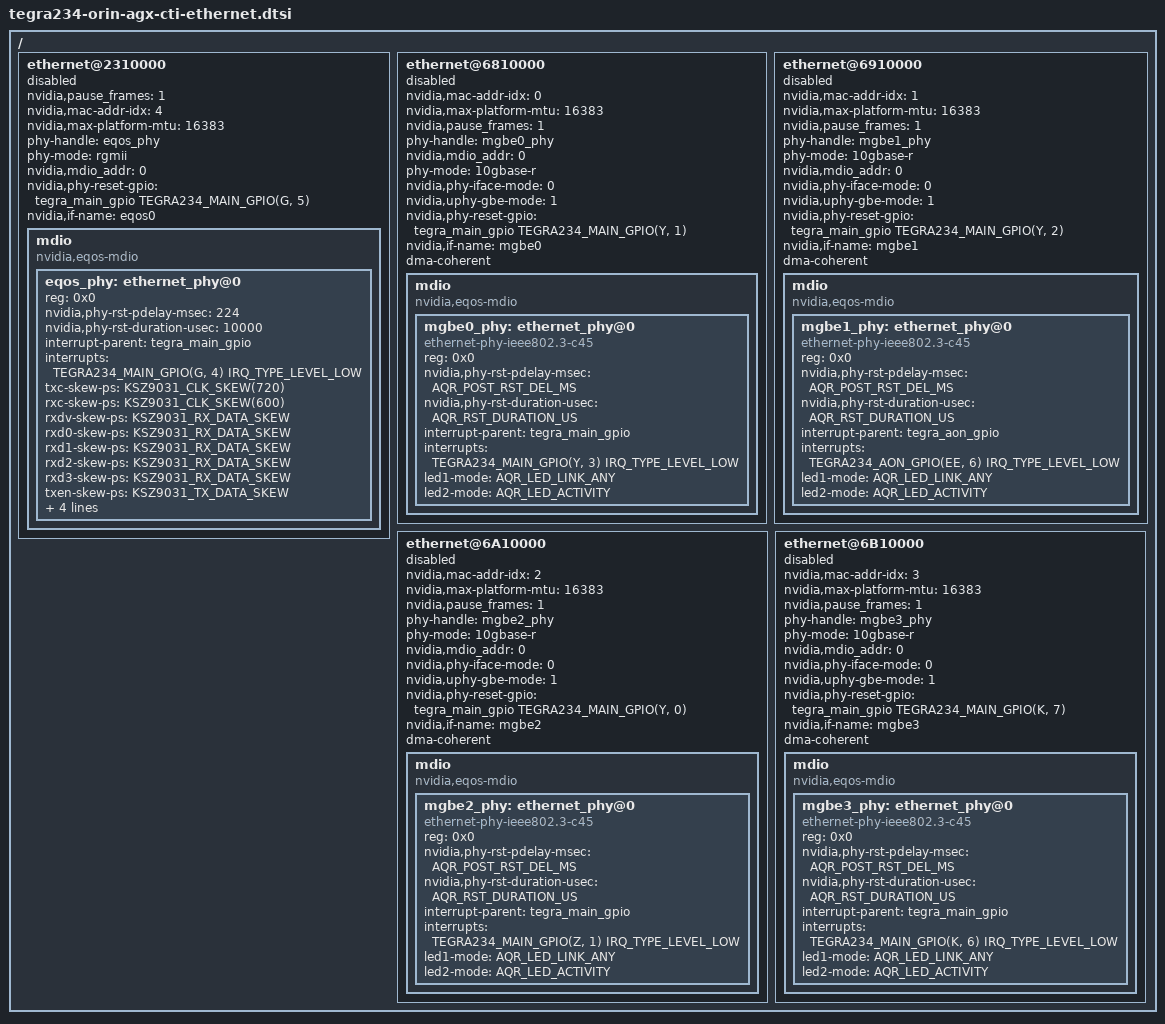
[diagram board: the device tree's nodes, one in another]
/*
 * Copyright (c) 2023, Connect Tech Inc.  All rights reserved.
 *
 * This program is free software; you can redistribute it and/or modify it
 * under the terms and conditions of the GNU General Public License,
 * version 2, as published by the Free Software Foundation.
 *
 * This program is distributed in the hope it will be useful, but WITHOUT
 * ANY WARRANTY; without even the implied warranty of MERCHANTABILITY or
 * FITNESS FOR A PARTICULAR PURPOSE.  See the GNU General Public License for
 * more details.
 *
 * You should have received a copy of the GNU General Public License
 * along with this program.  If not, see <http://www.gnu.org/licenses/>.
 */

#include <dt-bindings/gpio/tegra234-gpio.h>

//AQR113 LED Modes
#define AQR_LED_OFF         0x0000
#define AQR_LED_ACTIVITY    0x000F
#define AQR_LED_CONNECTING  0x0010
#define AQR_LED_LINK_100    0x0020
#define AQR_LED_LINK_1000   0x0040
#define AQR_LED_LINK_10000  0x0080
#define AQR_LED_LINK_10     0x2000
#define AQR_LED_LINK_2500   0x4000
#define AQR_LED_LINK_5000   0x8000
#define AQR_LED_LINK_ANY    0xE0E0

//Reset assert duration in microseconds
#define AQR_RST_DURATION_US 150000  //AQR113 min 100ms, using 150ms 

//Time to wait after reset in milliseconds
#define AQR_POST_RST_DEL_MS 1000     //Not specified in AQR113 DS, 1s is needed for FW to load

/*
 * Calculate the Device Tree Value for a Clk Skew Property
 * DT value of "900" is 0ps delay. Min is -900ps, max is +960ps 
 */
#define KSZ9031_CLK_SKEW(skew_ps) (900 + skew_ps)

/*
 * Calculate the Device Tree Value for a Data Skew Property
 * DT value of "420" is 0ps delay. Min is -400ps, max is +480ps 
 */
#define KSZ9031_DATA_SKEW(skew_ps) (420 + skew_ps)

#define KSZ9031_RX_DATA_SKEW KSZ9031_DATA_SKEW(0)   //0ns
#define KSZ9031_TX_DATA_SKEW KSZ9031_DATA_SKEW(0)   //0ns

/ {
    //EQOS 1GbE
    ethernet@2310000 {
		status = "disabled";
        nvidia,pause_frames = <1>;  //1=disabled
        nvidia,mac-addr-idx = <4>;
        nvidia,max-platform-mtu = <16383>;
		phy-handle = <&eqos_phy>;
        //Use RGMII not RGMII-ID (Internal Delay) to set custom skew values
        phy-mode = "rgmii";
        nvidia,mdio_addr = <0>;

        nvidia,phy-reset-gpio = <&tegra_main_gpio TEGRA234_MAIN_GPIO(G, 5) 0>;

        nvidia,if-name = "eqos0";

		mdio {
			compatible = "nvidia,eqos-mdio";
			#address-cells = <1>;
            #size-cells = <0>;
            eqos_phy: ethernet_phy@0 {
                reg = <0x0>;
                nvidia,phy-rst-pdelay-msec = <224>;
                nvidia,phy-rst-duration-usec = <10000>;
                interrupt-parent = <&tegra_main_gpio>;
                interrupts = <TEGRA234_MAIN_GPIO(G, 4) IRQ_TYPE_LEVEL_LOW>;

                //Clk to Data skew must be 1.5ns-2.0ns
                txc-skew-ps  = <KSZ9031_CLK_SKEW(720)>; //+0.72ns + +1.1ns (on-board) = +1.82ns 
                rxc-skew-ps  = <KSZ9031_CLK_SKEW(600)>; //+0.60ns + +1.2ns (built-in) = +1.80ns

                rxdv-skew-ps = <KSZ9031_RX_DATA_SKEW>; 
                rxd0-skew-ps = <KSZ9031_RX_DATA_SKEW>;
                rxd1-skew-ps = <KSZ9031_RX_DATA_SKEW>;
                rxd2-skew-ps = <KSZ9031_RX_DATA_SKEW>;
                rxd3-skew-ps = <KSZ9031_RX_DATA_SKEW>;

                txen-skew-ps = <KSZ9031_TX_DATA_SKEW>;
                txd0-skew-ps = <KSZ9031_TX_DATA_SKEW>;
                txd1-skew-ps = <KSZ9031_TX_DATA_SKEW>;
                txd2-skew-ps = <KSZ9031_TX_DATA_SKEW>;
                txd3-skew-ps = <KSZ9031_TX_DATA_SKEW>;

            };
        };
    }; 

	//MGBE 0
	ethernet@6810000 {
		status = "disabled";
		nvidia,mac-addr-idx = <0>;
		nvidia,max-platform-mtu = <16383>;

		/* 1=enable, 0=disable */
		nvidia,pause_frames = <1>; //changed from 0!!!
		phy-handle = <&mgbe0_phy>;
        nvidia,mdio_addr = <0>;
		phy-mode = "10gbase-r";

		/* 0:XFI 10G, 1:XFI 5G, 2:USXGMII 10G, 3:USXGMII 5G */
		nvidia,phy-iface-mode = <0>;
        /* 1 = 10G, 0 = 5G*/
        nvidia,uphy-gbe-mode = <1>;
        nvidia,phy-reset-gpio = <&tegra_main_gpio TEGRA234_MAIN_GPIO(Y, 1) 0>;

        nvidia,if-name = "mgbe0";

        dma-coherent;

		mdio {
			compatible = "nvidia,eqos-mdio";
			#address-cells = <1>;
			#size-cells = <0>;

			mgbe0_phy: ethernet_phy@0 {
				compatible = "ethernet-phy-ieee802.3-c45";
				reg = <0x0>;
                nvidia,phy-rst-pdelay-msec = <AQR_POST_RST_DEL_MS>; 
				nvidia,phy-rst-duration-usec = <AQR_RST_DURATION_US>;
				interrupt-parent = <&tegra_main_gpio>;
				interrupts = <TEGRA234_MAIN_GPIO(Y, 3) IRQ_TYPE_LEVEL_LOW>;
                led1-mode = <AQR_LED_LINK_ANY>;
                led2-mode = <AQR_LED_ACTIVITY>;
			};
		};
	};

	//MGBE 1
    ethernet@6910000 {
		status = "disabled";
		nvidia,mac-addr-idx = <1>;
		nvidia,max-platform-mtu = <16383>;

		/* 1=enable, 0=disable */
		nvidia,pause_frames = <1>;
		phy-handle = <&mgbe1_phy>;
		phy-mode = "10gbase-r";

        nvidia,mdio_addr = <0>;

		/* 0:XFI 10G, 1:XFI 5G, 2:USXGMII 10G, 3:USXGMII 5G */
		nvidia,phy-iface-mode = <0>;
        /* 1 = 10G, 0 = 5G*/
        nvidia,uphy-gbe-mode = <1>;
        nvidia,phy-reset-gpio = <&tegra_main_gpio TEGRA234_MAIN_GPIO(Y, 2) 0>;

        nvidia,if-name = "mgbe1";

        dma-coherent;

		mdio {
			compatible = "nvidia,eqos-mdio";
			#address-cells = <1>;
			#size-cells = <0>;
			mgbe1_phy: ethernet_phy@0 {
				compatible = "ethernet-phy-ieee802.3-c45";
				reg = <0x0>;
                nvidia,phy-rst-pdelay-msec = <AQR_POST_RST_DEL_MS>; 
				nvidia,phy-rst-duration-usec = <AQR_RST_DURATION_US>;
				interrupt-parent = <&tegra_aon_gpio>;
				interrupts = <TEGRA234_AON_GPIO(EE, 6) IRQ_TYPE_LEVEL_LOW>;
                led1-mode = <AQR_LED_LINK_ANY>;
                led2-mode = <AQR_LED_ACTIVITY>;
			};
        };

    };

	//MGBE 2
    ethernet@6A10000 {
		status = "disabled";
		nvidia,mac-addr-idx = <2>;
		nvidia,max-platform-mtu = <16383>;

		/* 1=enable, 0=disable */
		nvidia,pause_frames = <1>;
		phy-handle = <&mgbe2_phy>;
		phy-mode = "10gbase-r";
        nvidia,mdio_addr = <0>;

		/* 0:XFI 10G, 1:XFI 5G, 2:USXGMII 10G, 3:USXGMII 5G */
		nvidia,phy-iface-mode = <0>;
        /* 1 = 10G, 0 = 5G*/
        nvidia,uphy-gbe-mode = <1>;
        nvidia,phy-reset-gpio = <&tegra_main_gpio TEGRA234_MAIN_GPIO(Y, 0) 0>;

        nvidia,if-name = "mgbe2";

        dma-coherent;

		mdio {
			compatible = "nvidia,eqos-mdio";
			#address-cells = <1>;
			#size-cells = <0>;
			mgbe2_phy: ethernet_phy@0 {
				compatible = "ethernet-phy-ieee802.3-c45";
				reg = <0x0>;
                nvidia,phy-rst-pdelay-msec = <AQR_POST_RST_DEL_MS>; 
				nvidia,phy-rst-duration-usec = <AQR_RST_DURATION_US>;
				interrupt-parent = <&tegra_main_gpio>;
				interrupts = <TEGRA234_MAIN_GPIO(Z, 1) IRQ_TYPE_LEVEL_LOW>;
                led1-mode = <AQR_LED_LINK_ANY>;
                led2-mode = <AQR_LED_ACTIVITY>;
			};
        };
    };

	//MGBE 3
    ethernet@6B10000 {
		status = "disabled";
		nvidia,mac-addr-idx = <3>;
		nvidia,max-platform-mtu = <16383>;

		/* 1=enable, 0=disable */
		nvidia,pause_frames = <1>;
		phy-handle = <&mgbe3_phy>;
		phy-mode = "10gbase-r";
        nvidia,mdio_addr = <0>;

		/* 0:XFI 10G, 1:XFI 5G, 2:USXGMII 10G, 3:USXGMII 5G */
		nvidia,phy-iface-mode = <0>;
        /* 1 = 10G, 0 = 5G*/
        nvidia,uphy-gbe-mode = <1>;
        nvidia,phy-reset-gpio = <&tegra_main_gpio TEGRA234_MAIN_GPIO(K, 7) 0>;

        nvidia,if-name = "mgbe3";

        dma-coherent;

		mdio {
			compatible = "nvidia,eqos-mdio";
			#address-cells = <1>;
			#size-cells = <0>;

			mgbe3_phy: ethernet_phy@0 {
				compatible = "ethernet-phy-ieee802.3-c45";
				reg = <0x0>;
                nvidia,phy-rst-pdelay-msec = <AQR_POST_RST_DEL_MS>; 
				nvidia,phy-rst-duration-usec = <AQR_RST_DURATION_US>;
				interrupt-parent = <&tegra_main_gpio>;
				interrupts = <TEGRA234_MAIN_GPIO(K, 6) IRQ_TYPE_LEVEL_LOW>;
                led1-mode = <AQR_LED_LINK_ANY>;
                led2-mode = <AQR_LED_ACTIVITY>;
			};
        };
    };
};
